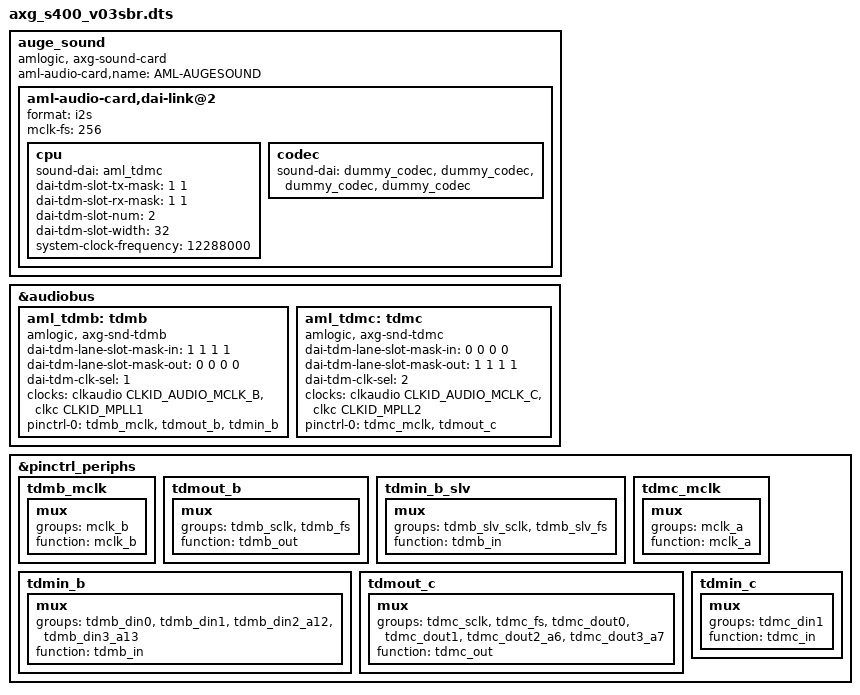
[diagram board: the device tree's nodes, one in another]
    auge_sound {
		compatible = "amlogic, axg-sound-card";
		aml-audio-card,name = "AML-AUGESOUND";

		aml-audio-card,dai-link@2 {
			format = "i2s";
			mclk-fs = <256>;
			//continuous-clock;
			//bitclock-inversion;
			//frame-inversion;
			//bitclock-master = <&aml_tdmc>;
			//frame-master = <&aml_tdmc>;
			cpu {
				sound-dai = <&aml_tdmc>;
				dai-tdm-slot-tx-mask = <1 1>;
				dai-tdm-slot-rx-mask = <1 1>;
				dai-tdm-slot-num = <2>;
				dai-tdm-slot-width = <32>;
				system-clock-frequency = <12288000>;
			};
			codec {
				//prefix-names = "5707_A", "5707_B", "5707_C", "5707_D";
				sound-dai = <&dummy_codec &dummy_codec &dummy_codec &dummy_codec>;
			};
		};
	};

&audiobus {
	aml_tdmb: tdmb {
		compatible = "amlogic, axg-snd-tdmb";
		#sound-dai-cells = <0>;
		dai-tdm-lane-slot-mask-in = <1 1 1 1>;
		dai-tdm-lane-slot-mask-out = <0 0 0 0>;
		dai-tdm-clk-sel = <1>;
		clocks = <&clkaudio CLKID_AUDIO_MCLK_B
				&clkc CLKID_MPLL1>;
		clock-names = "mclk", "clk_srcpll";
		pinctrl-names = "tdm_pins";

		/*A113D tdmb slave for HDMI*/
		//pinctrl-0 = <&tdmb_mclk &tdmin_b_slv &tdmin_b>;

		/*A113D tdmb master for LineIn*/
		
		  pinctrl-0 = <&tdmb_mclk &tdmout_b &tdmin_b>;
		
	};

	aml_tdmc: tdmc {
		compatible = "amlogic, axg-snd-tdmc";
		#sound-dai-cells = <0>;
		dai-tdm-lane-slot-mask-in = <0 0 0 0>;
		dai-tdm-lane-slot-mask-out = <1 1 1 1>;
		dai-tdm-clk-sel = <2>;
		clocks = <&clkaudio CLKID_AUDIO_MCLK_C
				&clkc CLKID_MPLL2>;
		clock-names = "mclk", "clk_srcpll";
		pinctrl-names = "tdm_pins";
		pinctrl-0 = <&tdmc_mclk &tdmout_c>;
	};
}; /* end of audiobus */

&pinctrl_periphs {
	tdmb_mclk: tdmb_mclk {
		mux {
			groups = "mclk_b";
			function = "mclk_b";
		};
	};

	tdmout_b: tdmout_b {
		mux {
			groups = "tdmb_sclk",
				"tdmb_fs";
			function = "tdmb_out";
		};
	};

	tdmin_b_slv: tdmin_b_slv{
		mux {
			groups = "tdmb_slv_sclk", "tdmb_slv_fs";
			function = "tdmb_in";
		};
	};

	// tdmin and tdmout are the same pins. can't use at same time
	tdmin_b:tdmin_b {
		mux {
			groups = "tdmb_din0",
				"tdmb_din1",
				"tdmb_din2_a12",
				"tdmb_din3_a13";
			function = "tdmb_in";
		};
	};

	tdmc_mclk: tdmc_mclk {
		mux {
			groups = "mclk_a";
			function = "mclk_a";
		};
	};

	tdmout_c:tdmout_c {
		mux {
			groups = "tdmc_sclk",
				"tdmc_fs",
				"tdmc_dout0",
				"tdmc_dout1",
				"tdmc_dout2_a6",
				"tdmc_dout3_a7";
			function = "tdmc_out";
		};
	};


	tdmin_c:tdmin_c {
		mux {
			groups = "tdmc_din1";
			function = "tdmc_in";
		};
	};
}; /* end of pinctrl_periphs */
